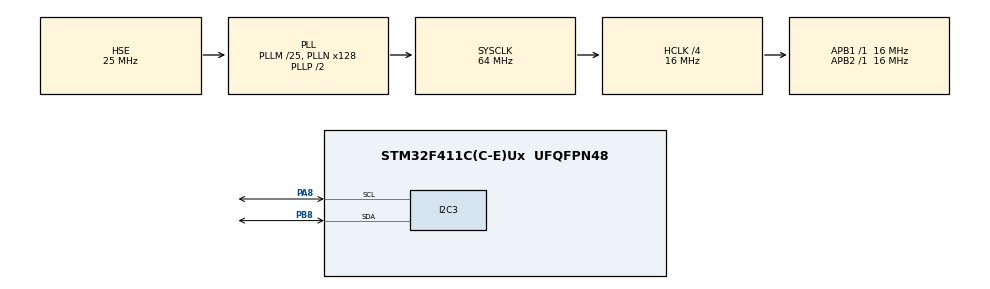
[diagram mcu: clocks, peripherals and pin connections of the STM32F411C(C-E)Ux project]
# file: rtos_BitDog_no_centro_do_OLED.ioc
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FREERTOS.Tasks01=oledTask,24,128,OledTask,Default,NULL,Dynamic,NULL,NULL
FREERTOS.configUSE_NEWLIB_REENTRANT=1
Mcu.Family=STM32F4
Mcu.Name=STM32F411C(C-E)Ux
Mcu.Package=UFQFPN48
NVIC.PriorityGroup=NVIC_PRIORITYGROUP_4
NVIC.TIM2_IRQn=true\:15\:0\:false\:false\:true\:false\:false\:true\:true
NVIC.TimeBase=TIM2_IRQn
NVIC.TimeBaseIP=TIM2
PA13.Mode=Serial_Wire
PA13.Signal=SYS_JTMS-SWDIO
PA14.Mode=Serial_Wire
PA14.Signal=SYS_JTCK-SWCLK
PA8.Mode=I2C
PA8.Signal=I2C3_SCL
PB8.Mode=I2C
PB8.Signal=I2C3_SDA
PH0\ -\ OSC_IN.Mode=HSE-External-Oscillator
PH0\ -\ OSC_IN.Signal=RCC_OSC_IN
PH1\ -\ OSC_OUT.Mode=HSE-External-Oscillator
PH1\ -\ OSC_OUT.Signal=RCC_OSC_OUT
ProjectManager.HeapSize=0x200
ProjectManager.StackSize=0x400
ProjectManager.TargetToolchain=STM32CubeIDE
RCC.48MHZClocksFreq_Value=32000000
RCC.AHBCLKDivider=RCC_SYSCLK_DIV4
RCC.AHBFreq_Value=16000000
RCC.APB1Freq_Value=16000000
RCC.APB1TimFreq_Value=16000000
RCC.APB2Freq_Value=16000000
RCC.APB2TimFreq_Value=16000000
RCC.CortexFreq_Value=16000000
RCC.HCLKFreq_Value=16000000
RCC.HSE_VALUE=25000000
RCC.HSI_VALUE=16000000
RCC.LSE_VALUE=32768
RCC.PLLM=25
RCC.PLLN=128
RCC.PLLSourceVirtual=RCC_PLLSOURCE_HSE
RCC.SYSCLKFreq_VALUE=64000000
RCC.SYSCLKSource=RCC_SYSCLKSOURCE_PLLCLK
RCC.VCOOutputFreq_Value=128000000
VP_FREERTOS_VS_CMSIS_V2.Mode=CMSIS_V2
VP_SYS_VS_tim2.Mode=TIM2
board=custom

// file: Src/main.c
/* USER CODE BEGIN Header */
/**
  ******************************************************************************
  * @file           : main.c
  * @brief          : Ponto de entrada da aplicação com FreeRTOS e display OLED. É
  * 					a versão do BitDog_no_centro_do_OLED em RTOS
  * @author 		: Wu Shin Ting
  * @date			: 20/03/2026
  ******************************************************************************
  * @attention
  *
  * Copyright (c) 2026 STMicroelectronics.
  * All rights reserved.
  *
  * This software is licensed under terms that can be found in the LICENSE file
  * in the root directory of this software component.
  * If no LICENSE file comes with this software, it is provided AS-IS.
  *
  ******************************************************************************
  * @section overview Visão Geral
  *
  * Este projeto demonstra o uso de um sistema embarcado baseado em FreeRTOS
  * para exibição de uma imagem monocromática em um display OLED controlado
  * pelo driver SSD1306 via interface I2C.
  *
  * A aplicação segue uma arquitetura baseada em tarefas, onde a lógica de
  * exibição é delegada a uma thread específica (OledTask), permitindo
  * escalabilidade futura para inclusão de novos módulos (sensores, comunicação,
  * interface de usuário, etc.).
  *
  * O fluxo principal do sistema é:
  * - Inicialização de hardware (HAL + periféricos)
  * - Inicialização do display OLED
  * - Inicialização do kernel do FreeRTOS
  * - Criação das tarefas
  * - Execução do scheduler
  *
  * Após o início do scheduler, o controle do sistema deixa de ser sequencial
  * e passa a ser gerenciado pelo kernel do RTOS.
  *
  * @section user_code Código Implementado Manualmente
  *
  * As principais partes implementadas manualmente neste arquivo são:
  *
  * - Integração com o FreeRTOS:
  *   @code
  *   osKernelInitialize();
  *   MX_FREERTOS_Init();
  *   osKernelStart();
  *   @endcode
  *
  * @note
  * - A lógica de renderização da imagem não está neste arquivo, mas sim
  * encapsulada na tarefa OledTask definida em freertos.c.
  *
  * - O driver do display está disponível na biblioteca estática libhal_BDL_Library.a.
  * Consulte a configuração do projeto (Properties > C/C++ Build > Settings) para ver
  * como a biblioteca é vinculada sem a necessidade de copiar os arquivos-fonte.
  *
  * @section mental_model Modelo Mental do Sistema
  *
  * Uma forma simples de entender o funcionamento do sistema é:
  *
  * @code
  * [main()]
  *    |
  *    |--> Inicializa hardware (HAL, GPIO, I2C)
  *    |--> Inicializa display (SSD1306)
  *    |--> Inicializa RTOS
  *            |
  *            |--> Cria OledTask
  *            |
  *            --> Scheduler assume o controle
  *                         |
  *                         --> Executa OledTask em loop
  *                                |
  *                                --> Atualiza display OLED
  * @endcode
  *
  * Ou seja, após o scheduler iniciar:
  * - O main() deixa de executar lógica ativa
  * - Toda a aplicação passa a rodar dentro das tarefas do RTOS
  *
  * @section cube_config Configuração no CubeMX
  *
  * A configuração do projeto foi realizada utilizando o STM32CubeMX, com os
  * seguintes pontos principais:
  *
  * - Middleware:
  *   - FreeRTOS habilitado (CMSIS-RTOS v2)
  *
  * - Periféricos:
  *   - I2C3 configurado para comunicação com o display SSD1306
  *   - GPIO inicializado conforme necessário
  *
  * - Clock:
  *   - Configurado via SystemClock_Config()
  *
  * - Gerenciamento de código:
  *   - Separação entre código gerado automaticamente e USER CODE
  *   - Arquivo freertos.c responsável pelas tarefas
  *
  * @note
  * Qualquer alteração estrutural (periféricos, RTOS, clock) deve ser feita
  * preferencialmente via CubeMX para manter a consistência do projeto.
  *
  * @warning
  * Este projeto utiliza o FreeRTOS de forma propositalmente simplificada e
  * NÃO representa uma boa prática de uso do RTOS em sistemas embarcados reais.
  *
  * A tarefa criada (OledTask) executa em loop infinito redesenhando uma imagem
  * estática no display OLED, o que resulta em:
  * - uso desnecessário de CPU
  * - atualizações redundantes do display
  * - ausência de modelo orientado a eventos (event-driven)
  *
  * Em um projeto bem estruturado com RTOS, o display deveria ser atualizado:
  * - apenas quando houver mudança de estado
  * - a partir de eventos (filas, semáforos ou notificações)
  * - com possível compartilhamento seguro de recursos (ex: barramento I2C)
  *
  * Além disso, a renderização pixel a pixel não é eficiente e poderia ser
  * substituída por operações em bloco no framebuffer.
  *
  * Portanto, este projeto tem como objetivo apenas demonstrar:
  * - a migração de um projeto baseado em HAL para uma arquitetura com RTOS
  * - a criação e execução de tarefas no FreeRTOS
  *
  * Não deve ser utilizado como referência de arquitetura para aplicações finais.
 */
/* USER CODE END Header */
#include "main.h"
#include "cmsis_os.h"
#include "i2c.h"
#include "gpio.h"

void SystemClock_Config(void);
void MX_FREERTOS_Init(void);

int main(void)
{

  /* MCU Configuration--------------------------------------------------------*/

  /* Reset of all peripherals, Initializes the Flash interface and the Systick. */
  HAL_Init();

  /* Configure the system clock */
  SystemClock_Config();

  /* Initialize all configured peripherals */
  MX_GPIO_Init();
  MX_I2C3_Init();

  /* Init scheduler */
  osKernelInitialize();  /* Call init function for freertos objects (in cmsis_os2.c) */
  MX_FREERTOS_Init();

  /* Start scheduler */
  osKernelStart();

  /* We should never get here as control is now taken by the scheduler */

  /* Infinite loop */
  while (1)
  {

  }
}

void SystemClock_Config(void)
{
  RCC_OscInitTypeDef RCC_OscInitStruct = {0};
  RCC_ClkInitTypeDef RCC_ClkInitStruct = {0};

  /** Configure the main internal regulator output voltage
  */
  __HAL_RCC_PWR_CLK_ENABLE();
  __HAL_PWR_VOLTAGESCALING_CONFIG(PWR_REGULATOR_VOLTAGE_SCALE1);

  /** Initializes the RCC Oscillators according to the specified parameters
  * in the RCC_OscInitTypeDef structure.
  */
  RCC_OscInitStruct.OscillatorType = RCC_OSCILLATORTYPE_HSE;
  RCC_OscInitStruct.HSEState = RCC_HSE_ON;
  RCC_OscInitStruct.PLL.PLLState = RCC_PLL_ON;
  RCC_OscInitStruct.PLL.PLLSource = RCC_PLLSOURCE_HSE;
  RCC_OscInitStruct.PLL.PLLM = 25;
  RCC_OscInitStruct.PLL.PLLN = 128;
  RCC_OscInitStruct.PLL.PLLP = RCC_PLLP_DIV2;
  RCC_OscInitStruct.PLL.PLLQ = 4;
  if (HAL_RCC_OscConfig(&RCC_OscInitStruct) != HAL_OK)
  {
    Error_Handler();
  }

  /** Initializes the CPU, AHB and APB buses clocks
  */
  RCC_ClkInitStruct.ClockType = RCC_CLOCKTYPE_HCLK|RCC_CLOCKTYPE_SYSCLK
                              |RCC_CLOCKTYPE_PCLK1|RCC_CLOCKTYPE_PCLK2;
  RCC_ClkInitStruct.SYSCLKSource = RCC_SYSCLKSOURCE_PLLCLK;
  RCC_ClkInitStruct.AHBCLKDivider = RCC_SYSCLK_DIV4;
  RCC_ClkInitStruct.APB1CLKDivider = RCC_HCLK_DIV1;
  RCC_ClkInitStruct.APB2CLKDivider = RCC_HCLK_DIV1;

  if (HAL_RCC_ClockConfig(&RCC_ClkInitStruct, FLASH_LATENCY_0) != HAL_OK)
  {
    Error_Handler();
  }
}

void HAL_TIM_PeriodElapsedCallback(TIM_HandleTypeDef *htim)
{
  if (htim->Instance == TIM2)
  {
    HAL_IncTick();
  }
}

void Error_Handler(void)
{
  __disable_irq();
  while (1)
  {
  }
}

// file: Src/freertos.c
/* USER CODE BEGIN Header */
/**
  ******************************************************************************
  * @file          : freertos.c
  * @brief         : Configuração e implementação das tarefas do sistema utilizando FreeRTOS.
  * @author 	   : Wu Shin Ting
  * @date		   : 20/03/2026
  ******************************************************************************
  * @attention
  *
  * Copyright (c) 2026 STMicroelectronics.
  * All rights reserved.
  *
  * This software is licensed under terms that can be found in the LICENSE file
  * in the root directory of this software component.
  * If no LICENSE file comes with this software, it is provided AS-IS.
  *
  ******************************************************************************
 * @details
 * Este arquivo contém a inicialização do kernel do FreeRTOS e a criação das
 * tarefas da aplicação. O sistema atual possui uma única tarefa responsável
 * pelo controle e atualização de um display OLED baseado no controlador SSD1306.
 *
 * O sistema possui 1 tarefa:
 * @li OledTask
 *     - Prioridade: Normal (osPriorityNormal)
 *     - Stack: 512 bytes
 *     - Função: Controle do display OLED
 *
 * A tarefa OledTask é responsável por iniciar o driver ssd1306 e gerenciar a saída gráfica
 * no display OLED.
 *
 * @note
 * - A renderização é feita de forma manual e pode ser otimizada utilizando
 *   operações em bloco no framebuffer.
 *
 * - Não há uso de mecanismos de sincronização (mutex, semáforos ou filas),
 *   pois existe apenas uma tarefa ativa no sistema.
 *
 * - O uso de RTOS neste caso permite escalabilidade futura, como a adição de
 *   novas tarefas (sensores, comunicação, interface, etc.).
 *
 * - A função osDelay() é utilizada para liberar a CPU para outras tarefas,
 *   evitando bloqueio ativo (busy wait).
 *
 */
/* USER CODE END Header */

#include "FreeRTOS.h"
#include "task.h"
#include "main.h"
#include "cmsis_os.h"

/* USER CODE BEGIN Includes */
#include "ssd1306.h"

/* USER CODE END Includes */

/* USER CODE BEGIN PD */
/* Ajuste necessário para alinhamento com o início da imagem */
#define OFFSET 6
/* USER CODE END PD */

/* USER CODE BEGIN Variables */
/* @brief O bitmap é utilizado para renderização manual no framebuffer do
 * display OLED SSD1306 por meio da função ssd1306_DrawPixel().
 *
 * Dimensões:
 * - Largura: 80 pixels
 * - Altura: 60 pixels
 *
 * Tamanho total:
 * - 80 x 60 / 8 = 600 bytes
 */
const uint8_t bitdog_big[600] = {
    0x00,0x00,0x00,0x00,0x18,0x00,0x00,0x00,0x00,0x00,0x00,0x00,0x00,0x00,0x3C,0x00,
    0x00,0x00,0x00,0x00,0x00,0x00,0x00,0x00,0x3E,0x00,0x00,0x00,0x00,0x00,0x00,0x00,
    0x00,0x00,0x37,0x00,0x00,0x00,0x00,0x00,0x00,0x00,0x00,0x01,0xF3,0x80,0x00,0x00,
    0x00,0x00,0x00,0x00,0x01,0xF9,0x80,0x00,0x00,0x00,0x00,0x00,0x00,0x01,0xB8,0xC0,
    0x00,0x00,0x00,0x00,0x00,0x00,0x00,0x98,0x78,0x00,0x00,0x00,0x00,0x00,0x00,0x00,
    0xC0,0x3F,0x80,0x00,0x00,0x00,0x00,0x00,0x00,0x01,0xC0,0x03,0xE0,0x00,0x00,0x00,
    0x00,0x00,0x00,0x0F,0x80,0x00,0x78,0x03,0xE0,0x00,0x00,0x0F,0xE0,0x1C,0x00,0x00,
    0x1E,0x0F,0xF8,0x00,0x00,0x3F,0xFC,0x70,0x00,0x00,0x07,0x7F,0xFE,0x00,0x00,0x7F,
    0xFE,0xE0,0x00,0x00,0x03,0xFF,0xFF,0x00,0x00,0xFF,0xFF,0x80,0x00,0x00,0x01,0xFF,
    0xFF,0x00,0x01,0xFF,0xFF,0x80,0x00,0x00,0x00,0xFF,0xFF,0x80,0x01,0xFF,0xFF,0x03,
    0xF0,0x0F,0x80,0xFF,0xFF,0xC0,0x03,0xFF,0xFE,0x07,0x38,0x1C,0xC0,0x7F,0xFF,0xC0,
    0x07,0xFF,0xFE,0x06,0x1C,0x30,0x60,0x7F,0xFF,0xE0,0x07,0xFF,0xF6,0x0C,0x0C,0x70,
    0x30,0x6F,0xFF,0xE0,0x07,0xFF,0xF6,0x0C,0x7E,0x7E,0x30,0x6F,0xFF,0xF0,0x0F,0xFF,
    0xF6,0x08,0xFE,0x7F,0x30,0x6F,0xFF,0xF0,0x0F,0xFF,0xF6,0x08,0xFE,0x7F,0x30,0x6F,
    0xFF,0xF8,0x1F,0xFF,0xE6,0x08,0xFE,0x7F,0x30,0x67,0xFF,0xF8,0x1F,0xFF,0xE6,0x08,
    0xFE,0x7F,0x30,0x67,0xFF,0xF8,0x1F,0xFF,0xE6,0x0C,0xFE,0x7F,0x30,0x67,0xFF,0xFC,
    0x3F,0xFF,0xE6,0x0C,0xFC,0x3E,0x30,0x47,0xFF,0xFC,0x3F,0xFF,0xE6,0x06,0x7C,0x3C,
    0x60,0x43,0xFF,0xFC,0x3F,0xFF,0xC6,0x03,0xF8,0x1F,0xC0,0x43,0xFF,0xFE,0x7F,0xFF,
    0xC2,0x01,0xF0,0x0F,0x80,0xC3,0xFF,0xFE,0x7F,0xFF,0x82,0x00,0x00,0x00,0x00,0xC1,
    0xFF,0xFE,0x7F,0xFF,0x82,0x00,0x00,0x00,0x00,0xC1,0xFF,0xFE,0x7F,0xFF,0x83,0x00,
    0x1E,0x78,0x00,0xC0,0xFF,0xFE,0x7F,0xFF,0x03,0xF0,0x3F,0xFC,0x07,0xE0,0xFF,0xFF,
    0xFF,0xFE,0x07,0xFE,0x3F,0xFC,0x3F,0xF0,0x7F,0xFF,0xFF,0xFE,0x0C,0x07,0xFF,0xFC,
    0xF0,0x18,0x7F,0xFF,0xFF,0xFC,0x18,0x00,0xFF,0xFF,0x80,0x0C,0x3F,0xFF,0xFF,0xFC,
    0x18,0x00,0x3F,0xFE,0x00,0x0C,0x1F,0xFF,0xFF,0xF8,0x30,0x00,0x1F,0xFC,0x00,0x06,
    0x0F,0xFF,0xFF,0xF0,0x20,0x00,0x0F,0xF8,0x00,0x06,0x07,0xFF,0xFF,0xE0,0x60,0x00,
    0x0F,0xF0,0x00,0x03,0x03,0xFF,0x7F,0x80,0x60,0x00,0x03,0xE0,0x00,0x03,0x00,0xFE,
    0x7E,0x00,0x67,0x03,0x01,0xC0,0x81,0xE3,0x00,0x3C,0x00,0x00,0x67,0x07,0x81,0x81,
    0xC1,0xE3,0x00,0x00,0x00,0x00,0x67,0x07,0x81,0x81,0xC1,0xE3,0x00,0x00,0x00,0x00,
    0x60,0x03,0x01,0x81,0xC0,0x03,0x00,0x00,0x00,0x00,0x60,0x00,0x01,0x80,0x00,0x03,
    0x00,0x00,0x00,0x00,0x63,0x00,0x01,0x80,0x01,0x83,0x00,0x00,0x00,0x00,0x63,0x80,
    0x01,0x80,0x03,0xC3,0x00,0x00,0x00,0x00,0x23,0x81,0x81,0x83,0x83,0xC6,0x00,0x00,
    0x00,0x00,0x33,0x83,0xC1,0x83,0x81,0x86,0x00,0x00,0x00,0x00,0x10,0x03,0xC1,0x83,
    0x80,0x06,0x00,0x00,0x00,0x00,0x18,0x31,0x81,0x81,0x1C,0x0C,0x00,0x00,0x00,0x00,
    0x0C,0x78,0x01,0x80,0x3C,0x18,0x00,0x00,0x00,0x00,0x06,0x78,0x01,0x80,0x1C,0x38,
    0x00,0x00,0x00,0x00,0x07,0x00,0x03,0xE0,0x08,0x70,0x00,0x00,0x00,0x00,0x01,0xC0,
    0x1F,0x7C,0x01,0xC0,0x00,0x00,0x00,0x00,0x00,0xFF,0xFC,0x1F,0xFF,0x80,0x00,0x00,
    0x00,0x00,0x00,0x1F,0xE0,0x03,0xFC,0x00,0x00,0x00,0x00,0x00,0x00,0x00,0x00,0x00,
    0x00,0x00,0x00,0x00
};
/* USER CODE END Variables */

/* Definitions for oledTask */
osThreadId_t oledTaskHandle;
const osThreadAttr_t oledTask_attributes = {
  .name = "oledTask",
  .stack_size = 128 * 4,
  .priority = (osPriority_t) osPriorityNormal,
};

void OledTask(void *argument);

void MX_FREERTOS_Init(void); /* (MISRA C 2004 rule 8.1) */

void MX_FREERTOS_Init(void) {

  /* Create the thread(s) */
  /* creation of oledTask */
  oledTaskHandle = osThreadNew(OledTask, NULL, &oledTask_attributes);

}

/* USER CODE BEGIN Header_OledTask */
/**
* @brief Function implementing the oledTask thread.
* @param argument: Not used
* @retval None
*
*  O comportamento desta tarefa é descrita a seguir:
*
* 1. Limpa o display (preenche com cor preta)
* 2. Atualiza o display físico
* 3. Aguarda 3 segundos (osDelay)
* 4. Renderiza manualmente um bitmap monocromático (80x60 pixels)
*    - O bitmap é armazenado em memória como um array linear de 600 bytes
*    - Cada byte representa 8 pixels horizontais (formato MONO_HLSB)
*    - A renderização é feita pixel a pixel utilizando ssd1306_DrawPixel()
*    - Um deslocamento horizontal (OFFSET) é aplicado ao índice do bitmap
* 5. Atualiza o display com a imagem desenhada
* 6. Aguarda 6 segundos
* 7. Repete o ciclo indefinidamente
*
*/
/* USER CODE END Header_OledTask */
void OledTask(void *argument)
{
	/* USER CODE BEGIN OledTask */
	/* Inicialiar o driver ssd1306 */
	ssd1306_Init();
	/* Infinite loop */
	for(;;)
	{
		ssd1306_Fill(Black);
		ssd1306_UpdateScreen();
		osDelay(3000);

		/* ===================== Desenho do Bitmap ===================== */

		/**
		 * @brief Desenha a imagem BitDog (versão grande) no framebuffer do SSD1306.
		 *
		 * A imagem possui resolução de 80×60 pixels e está armazenada em formato
		 * monocromático (1 bit por pixel), com organização horizontal e bit menos
		 * significativo primeiro (MONO_HLSB).
		 *
		 * Os dados da imagem estão contidos em um buffer linear de 600 bytes
		 * (10 bytes por linha × 60 linhas). Cada byte representa 8 pixels
		 * horizontais consecutivos.
		 *
		 * O acesso ao bitmap considera um deslocamento inicial (@ref OFFSET),
		 * permitindo compensar um offset horizontal presente na origem dos dados
		 * (por exemplo, quando a imagem foi extraída de um framebuffer maior ou
		 * com stride diferente).
		 *
		 * A posição de desenho (24, 2) foi escolhida para centralizar a imagem
		 * horizontalmente em um display de 128×64 pixels.
		 *
		 * Este código é funcionalmente equivalente à chamada em MicroPython:
		 * @code
		 * oled.blit(fbuf_bdbig, 24, 2)
		 * @endcode
		 *
		 * @note O código valida o índice do buffer para evitar acesso fora dos
		 *       limites do bitmap.
		 */
		for (uint8_t y = 0; y < 60; y++) {
			for (uint8_t x = 0; x < 10; x++) {
				/* Índice do byte no bitmap (MONO_HLSB) */
				uint32_t byte_index = OFFSET + y * 10 + x;
				if (byte_index < 600) {
					for (uint8_t bit = 0; bit < 8; bit++) {

						/* Bit correspondente ao pixel dentro do byte */
						uint8_t bit_mask = 1 << (bit & 0x07);

						/* Testa se o pixel está ativo */
						if (bitdog_big[byte_index] & bit_mask) {
							ssd1306_DrawPixel(24+(x*8+(7-bit)), 2+y, White);
						}
					}
				}
			}
		}
		ssd1306_UpdateScreen();
		osDelay(6000);
	}
	/* USER CODE END OledTask */
}
